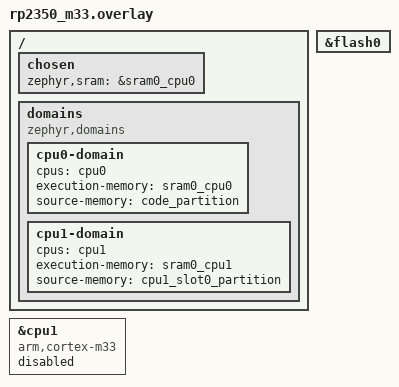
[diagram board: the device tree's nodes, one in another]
/*
 * Copyright (c) Qualcomm Technologies, Inc. and/or its subsidiaries.
 *
 * SPDX-License-Identifier: Apache-2.0
 */

#include <vendor/raspberrypi/rp2350_amp_sram_partitions.dtsi>

/ {
	chosen {
		zephyr,sram = &sram0_cpu0;
	};

	// cpu1-launcher {
	// 	compatible = "raspberrypi,pico-pcbs";
	// 	execution-memory = <&sram0_cpu1>;
	// 	source-memory = <&cpu1_slot0_partition>;
	// 	status = "okay";
	// };

    domains {
      compatible = "zephyr,domains";
	  status = "okay";
	  cpu0-domain {
        cpus = <&cpu0>;
        execution-memory = <&sram0_cpu0>;
        source-memory = <&code_partition>;
      };

      cpu1-domain {
        cpus = <&cpu1>;
        execution-memory = <&sram0_cpu1>;
        source-memory = <&cpu1_slot0_partition>;
      };
    };
};

&cpu1 {
	compatible = "arm,cortex-m33";
	// enable-method = "raspberrypi,pico-pcbs";
	status = "disabled";
};

&flash0 {
	/delete-node/ partitions;
};

#define WITH_CPU1_PARTITIONS
#include <vendor/raspberrypi/partitions_4M_default.dtsi>
